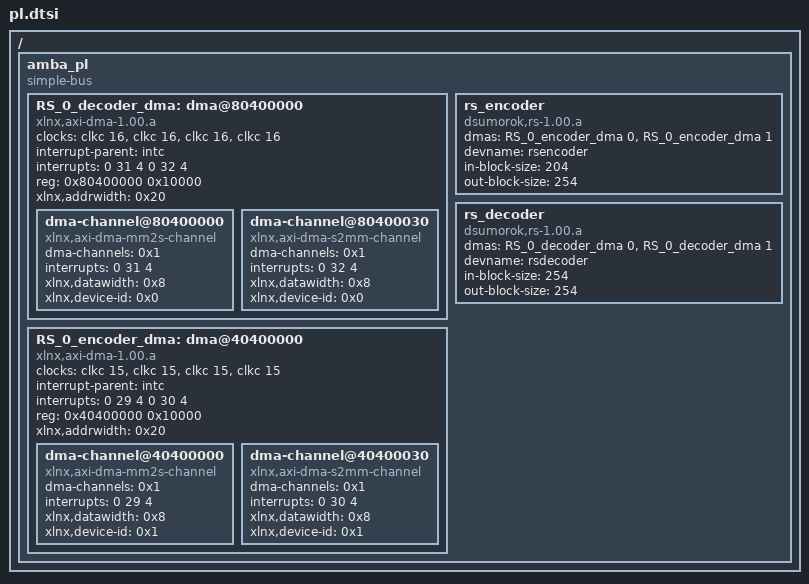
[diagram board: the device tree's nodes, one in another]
/*
 * CAUTION: This file is automatically generated by Xilinx.
 * Version:
 * Today is: Tue Jan  3 07:36:17 2017
*/


/ {
	amba_pl: amba_pl {
		#address-cells = <1>;
		#size-cells = <1>;
		compatible = "simple-bus";
		ranges ;
		RS_0_decoder_dma: dma@80400000 {
			#dma-cells = <1>;
			clock-names = "s_axi_lite_aclk", "m_axi_sg_aclk", "m_axi_mm2s_aclk", "m_axi_s2mm_aclk";
			clocks = <&clkc 16>, <&clkc 16>, <&clkc 16>, <&clkc 16>;
			compatible = "xlnx,axi-dma-1.00.a";
			interrupt-parent = <&intc>;
			interrupts = <0 31 4 0 32 4>;
			reg = <0x80400000 0x10000>;
			xlnx,addrwidth = <0x20>;
			dma-channel@80400000 {
				compatible = "xlnx,axi-dma-mm2s-channel";
				dma-channels = <0x1>;
				interrupts = <0 31 4>;
				xlnx,datawidth = <0x8>;
				xlnx,device-id = <0x0>;
			};
			dma-channel@80400030 {
				compatible = "xlnx,axi-dma-s2mm-channel";
				dma-channels = <0x1>;
				interrupts = <0 32 4>;
				xlnx,datawidth = <0x8>;
				xlnx,device-id = <0x0>;
			};
		};
		RS_0_encoder_dma: dma@40400000 {
			#dma-cells = <1>;
			clock-names = "s_axi_lite_aclk", "m_axi_sg_aclk", "m_axi_mm2s_aclk", "m_axi_s2mm_aclk";
			clocks = <&clkc 15>, <&clkc 15>, <&clkc 15>, <&clkc 15>;
			compatible = "xlnx,axi-dma-1.00.a";
			interrupt-parent = <&intc>;
			interrupts = <0 29 4 0 30 4>;
			reg = <0x40400000 0x10000>;
			xlnx,addrwidth = <0x20>;
			dma-channel@40400000 {
				compatible = "xlnx,axi-dma-mm2s-channel";
				dma-channels = <0x1>;
				interrupts = <0 29 4>;
				xlnx,datawidth = <0x8>;
				xlnx,device-id = <0x1>;
			};
			dma-channel@40400030 {
				compatible = "xlnx,axi-dma-s2mm-channel";
				dma-channels = <0x1>;
				interrupts = <0 30 4>;
				xlnx,datawidth = <0x8>;
				xlnx,device-id = <0x1>;
			};
		};

		rs_encoder {
			compatible = "dsumorok,rs-1.00.a";
			dmas = <&RS_0_encoder_dma 0>,
			       <&RS_0_encoder_dma 1>;
			dma-names = "toFPGA","fromFPGA";
			devname = "rsencoder";
			in-block-size = <204>;
			out-block-size = <254>;
		};

		rs_decoder {
			compatible = "dsumorok,rs-1.00.a";
			dmas = <&RS_0_decoder_dma 0>,
			       <&RS_0_decoder_dma 1>;
			dma-names = "toFPGA","fromFPGA";
			devname = "rsdecoder";
			in-block-size = <254>;
			out-block-size = <254>;
		};
	};
};
